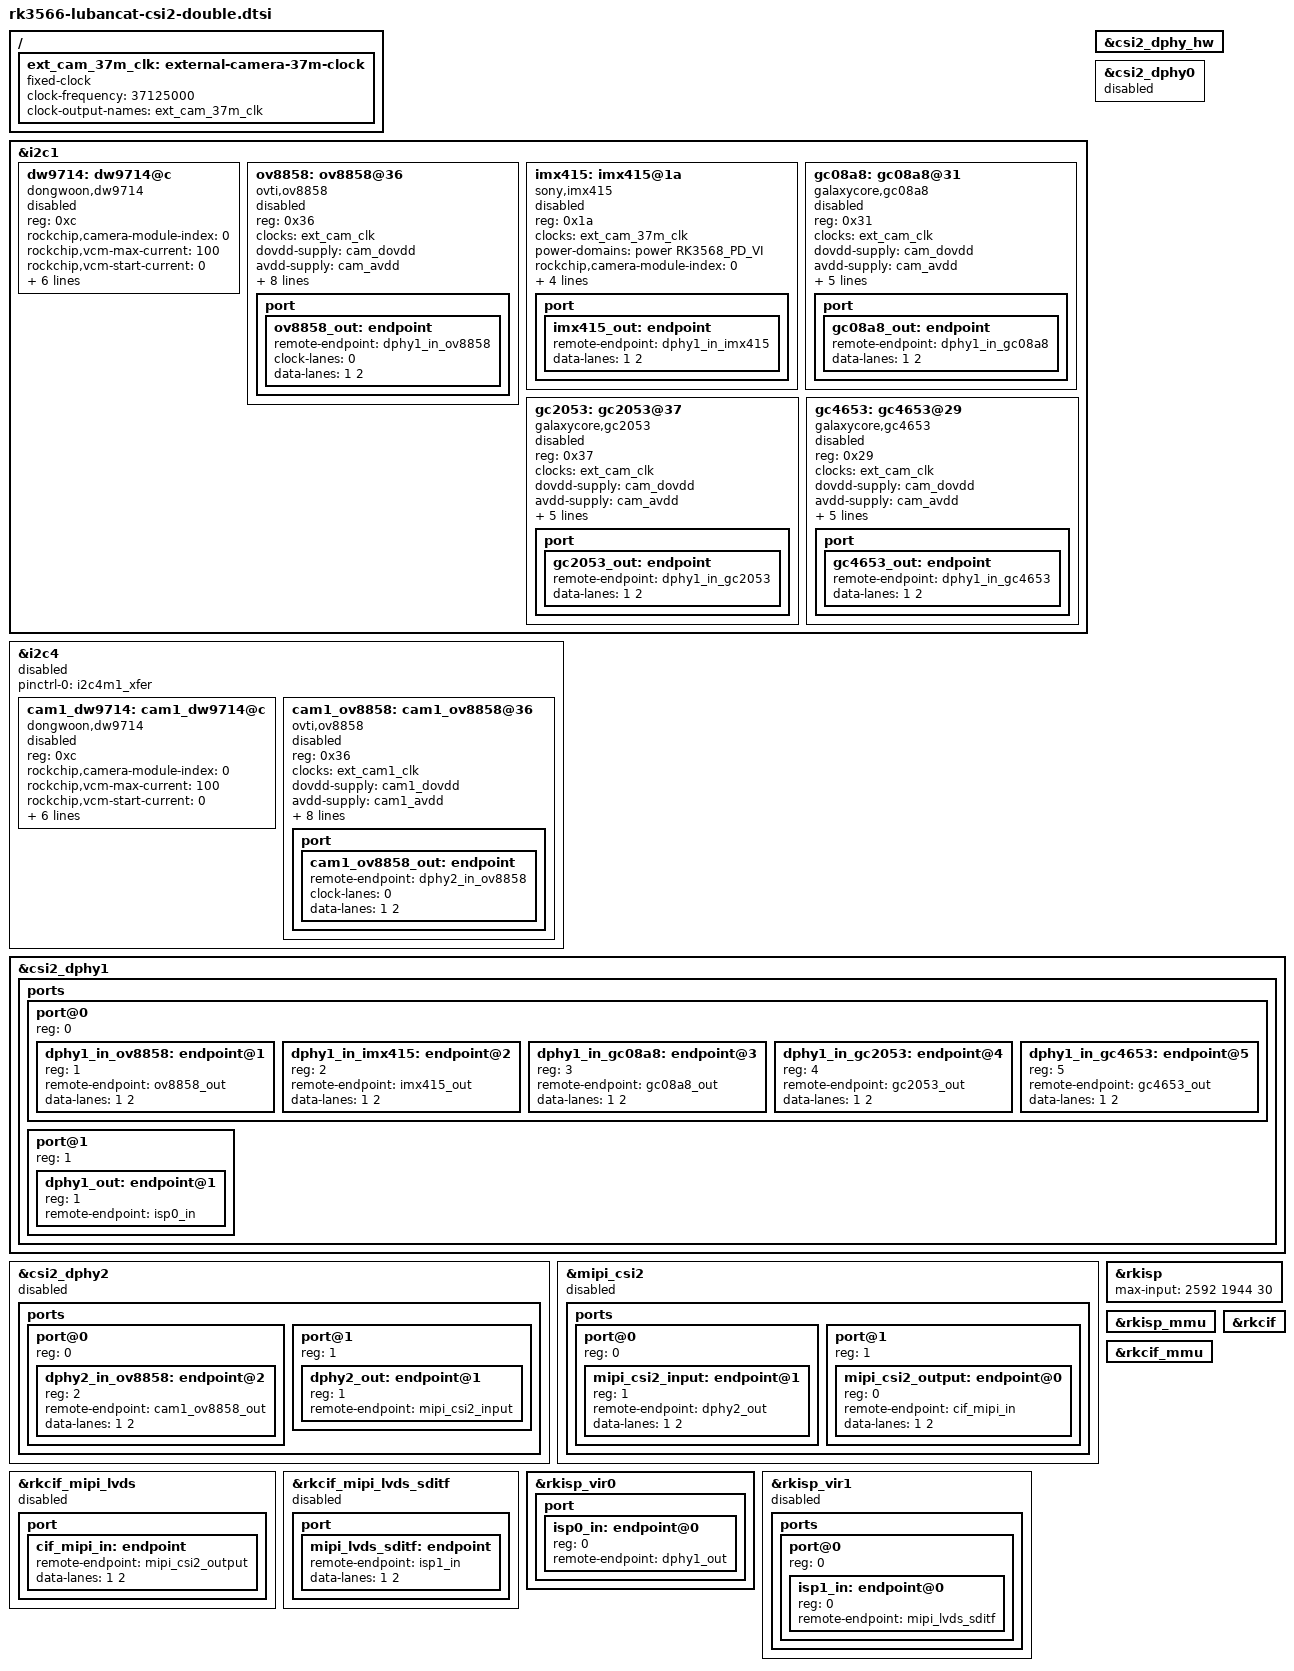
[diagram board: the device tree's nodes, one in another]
// SPDX-License-Identifier: (GPL-2.0+ OR MIT)
/ {
	ext_cam_37m_clk: external-camera-37m-clock {
		compatible = "fixed-clock";
		#clock-cells = <0>;
		clock-frequency = <37125000>;
		clock-output-names = "ext_cam_37m_clk";
	};
};

&i2c1 {
	status = "okay";
	// ov5648 Camare
	dw9714: dw9714@c {
		status = "disabled";
		compatible = "dongwoon,dw9714";
		reg = <0xc>;
		rockchip,camera-module-index = <0>;
		rockchip,vcm-max-current = <100>;
		rockchip,vcm-start-current = <0>;
		rockchip,vcm-rated-current = <100>;
		rockchip,vcm-step-mode = <0xd>;
		rockchip,vcm-dlc-enable = <0>;
		rockchip,vcm-mclk = <0>;
		rockchip,vcm-t-src = <0>;
		rockchip,camera-module-facing = "back";
	};

	ov8858: ov8858@36 {
		compatible = "ovti,ov8858";
		status = "disabled";
		reg = <0x36>;
		clocks = <&ext_cam_clk>;
		clock-names = "xvclk";
		dovdd-supply= <&cam_dovdd>; /* 1.8v */
		avdd-supply = <&cam_avdd>;  /* 2.8v */
		dvdd-supply = <&cam_dvdd>;  /* 1.2v */
		rotation = <180>;

		rockchip,camera-module-index = <0>;
		rockchip,camera-module-facing = "back";
		rockchip,camera-module-name = "HS5885-BNSM1018-V01";
		rockchip,camera-module-lens-name = "default";
		lens-focus = <&dw9714>;

		port {
			/* MIPI CSI-2 bus endpoint */
			ov8858_out: endpoint {
				remote-endpoint = <&dphy1_in_ov8858>;
				clock-lanes = <0>;
				data-lanes = <1 2>;
			};
		};
	};

	imx415: imx415@1a {
		status = "disabled";
		compatible = "sony,imx415";
		reg = <0x1a>;
		clocks = <&ext_cam_37m_clk>;
		clock-names = "xvclk";
		power-domains = <&power RK3568_PD_VI>;
		rockchip,camera-module-index = <0>;
		rockchip,camera-module-facing = "back";
		rockchip,camera-module-name = "CMK-OT1522-FG3";
		rockchip,camera-module-lens-name = "CS-P1150-IRC-8M-FAU";
		port {
			imx415_out: endpoint {
				remote-endpoint = <&dphy1_in_imx415>;
				data-lanes = <1 2>;
			};
		};
	};

	gc08a8: gc08a8@31 {
		compatible = "galaxycore,gc08a8";
		status = "disabled";
		reg = <0x31>;
		clocks = <&ext_cam_clk>;
		clock-names = "xvclk";
		dovdd-supply= <&cam_dovdd>; /* 1.8v */
		avdd-supply = <&cam_avdd>;  /* 2.8v */
		dvdd-supply = <&cam_dvdd>;  /* 1.2v */

		rockchip,camera-module-index = <0>;
		rockchip,camera-module-facing = "back";
		rockchip,camera-module-name = "YT10120";
		rockchip,camera-module-lens-name = "30IRC-4M-F20";

		port {
			gc08a8_out: endpoint {
				remote-endpoint = <&dphy1_in_gc08a8>;
				data-lanes = <1 2>;
			};
		};
	};

	gc2053: gc2053@37 {
		compatible = "galaxycore,gc2053";
		status = "disabled";
		reg = <0x37>;
		clocks = <&ext_cam_clk>;
		clock-names = "xvclk";
		dovdd-supply= <&cam_dovdd>; /* 1.8v */
		avdd-supply = <&cam_avdd>;  /* 2.8v */
		dvdd-supply = <&cam_dvdd>;  /* 1.2v */

		rockchip,camera-module-index = <0>;
		rockchip,camera-module-facing = "back";
		rockchip,camera-module-name = "SIDA205300461";
		rockchip,camera-module-lens-name = "60IRC-F20";

		port {
			gc2053_out: endpoint {
				remote-endpoint = <&dphy1_in_gc2053>;
				data-lanes = <1 2>;
			};
		};
	};

	gc4653: gc4653@29 {
		compatible = "galaxycore,gc4653";
		status = "disabled";
		reg = <0x29>;
		clocks = <&ext_cam_clk>;
		clock-names = "xvclk";
		dovdd-supply= <&cam_dovdd>; /* 1.8v */
		avdd-supply = <&cam_avdd>;  /* 2.8v */
		dvdd-supply = <&cam_dvdd>;  /* 1.2v */

		rockchip,camera-module-index = <0>;
		rockchip,camera-module-facing = "back";
		rockchip,camera-module-name = "YT10120";
		rockchip,camera-module-lens-name = "30IRC-4M-F20";

		port {
			gc4653_out: endpoint {
				remote-endpoint = <&dphy1_in_gc4653>;
				data-lanes = <1 2>;
			};
		};
	};
};

&i2c4 {
	pinctrl-names = "default";
	pinctrl-0 = <&i2c4m1_xfer>;
	status = "disabled";
	// ov5648 Camare
	cam1_dw9714: cam1_dw9714@c {
		status = "disabled";
		compatible = "dongwoon,dw9714";
		reg = <0xc>;
		rockchip,camera-module-index = <0>;
		rockchip,vcm-max-current = <100>;
		rockchip,vcm-start-current = <0>;
		rockchip,vcm-rated-current = <100>;
		rockchip,vcm-step-mode = <0xd>;
		rockchip,vcm-dlc-enable = <0>;
		rockchip,vcm-mclk = <0>;
		rockchip,vcm-t-src = <0>;
		rockchip,camera-module-facing = "front";
	};

	cam1_ov8858: cam1_ov8858@36 {
		compatible = "ovti,ov8858";
		status = "disabled";
		reg = <0x36>;
		clocks = <&ext_cam1_clk>;
		clock-names = "xvclk";
		dovdd-supply= <&cam1_dovdd>; /* 1.8v */
		avdd-supply = <&cam1_avdd>;  /* 2.8v */
		dvdd-supply = <&cam1_dvdd>;  /* 1.2v */
		rotation = <180>;

		rockchip,camera-module-index = <1>;
		rockchip,camera-module-facing = "front";
		rockchip,camera-module-name = "HS5885-BNSM1018-V01";
		rockchip,camera-module-lens-name = "default";
		lens-focus = <&cam1_dw9714>;

		port {
			/* MIPI CSI-2 bus endpoint */
			cam1_ov8858_out: endpoint {
				remote-endpoint = <&dphy2_in_ov8858>;
				clock-lanes = <0>;
				data-lanes = <1 2>;
			};
		};
	};
};

&csi2_dphy_hw {
	status = "okay";
};

&csi2_dphy0 {
	status = "disabled";
};

&csi2_dphy1 {
	status = "okay";

	ports {
		#address-cells = <1>;
		#size-cells = <0>;

		port@0 {
			reg = <0>;
			#address-cells = <1>;
			#size-cells = <0>;

			dphy1_in_ov8858: endpoint@1 {
				reg = <1>;
				remote-endpoint = <&ov8858_out>;
				data-lanes = <1 2>;
			};

			dphy1_in_imx415: endpoint@2 {
				reg = <2>;
				remote-endpoint = <&imx415_out>;
				data-lanes = <1 2>;
			};

			dphy1_in_gc08a8: endpoint@3 {
				reg = <3>;
				remote-endpoint = <&gc08a8_out>;
				data-lanes = <1 2>;
			};

			dphy1_in_gc2053: endpoint@4 {
				reg = <4>;
				remote-endpoint = <&gc2053_out>;
				data-lanes = <1 2>;
			};

			dphy1_in_gc4653: endpoint@5 {
				reg = <5>;
				remote-endpoint = <&gc4653_out>;
				data-lanes = <1 2>;
			};
		};

		port@1 {
			reg = <1>;
			#address-cells = <1>;
			#size-cells = <0>;

			dphy1_out: endpoint@1 {
				reg = <1>;
				remote-endpoint = <&isp0_in>;
			};
		};
	};
};

&csi2_dphy2 {
	status = "disabled";

	ports {
		#address-cells = <1>;
		#size-cells = <0>;

		port@0 {
			reg = <0>;
			#address-cells = <1>;
			#size-cells = <0>;

			dphy2_in_ov8858: endpoint@2 {
				reg = <2>;
				remote-endpoint = <&cam1_ov8858_out>;
				data-lanes = <1 2>;
			};
		};

		port@1 {
			reg = <1>;
			#address-cells = <1>;
			#size-cells = <0>;

			dphy2_out: endpoint@1 {
				reg = <1>;
				remote-endpoint = <&mipi_csi2_input>;
			};
		};
	};
};

&mipi_csi2 {
	status = "disabled";
	ports {
		#address-cells = <1>;
		#size-cells = <0>;

		port@0 {
			reg = <0>;
			#address-cells = <1>;
			#size-cells = <0>;

			mipi_csi2_input: endpoint@1 {
					reg = <1>;
					remote-endpoint = <&dphy2_out>;
					data-lanes = <1 2>;
			};
		};

		port@1 {
			reg = <1>;
			#address-cells = <1>;
			#size-cells = <0>;

			mipi_csi2_output: endpoint@0 {
					reg = <0>;
					remote-endpoint = <&cif_mipi_in>;
					data-lanes = <1 2>;
			};
		};
	};
};

&rkcif_mipi_lvds {
	status = "disabled";
	port {
		cif_mipi_in: endpoint {
			remote-endpoint = <&mipi_csi2_output>;
			data-lanes = <1 2>;
		};
	};
};

&rkcif_mipi_lvds_sditf {
	status = "disabled";
	port {
		mipi_lvds_sditf: endpoint {
			remote-endpoint = <&isp1_in>;
			data-lanes = <1 2>;
		};
	};
};

&rkisp {
	status = "okay";
	max-input = <2592 1944 30>;
};

&rkisp_mmu {
	status = "okay";
};

&rkisp_vir0 {
	status = "okay";

	port {
		#address-cells = <1>;
		#size-cells = <0>;

		isp0_in: endpoint@0 {
			reg = <0>;
			// csi2 dphy端的 port名
			remote-endpoint = <&dphy1_out>;
		};
	};
};

&rkisp_vir1 {
	status = "disabled";
	ports {
		#address-cells = <1>;
		#size-cells = <0>;
		port@0 {
			reg = <0>;
			#address-cells = <1>;
			#size-cells = <0>;

			isp1_in: endpoint@0 {
				reg = <0>;
				remote-endpoint = <&mipi_lvds_sditf>;
			};
		};
	};
};

&rkcif_mmu {
	status = "okay";
};

&rkcif {
	status = "okay";
};
